# STM32H7R register map
File version: 1.3
CPU: CM7 r0p1, little endian, MPU, FPU, 4 interrupt priority bits
Registers are 32-bit, read-write, reset 0x0 unless marked. A register's access mark holds for its fields unless they carry their own. Offsets are from the block's base; [hi:lo] are bit positions; <NAME> marks a mode.

## SPDIFRX — SPDIF receiver interface
Base 0x40004000
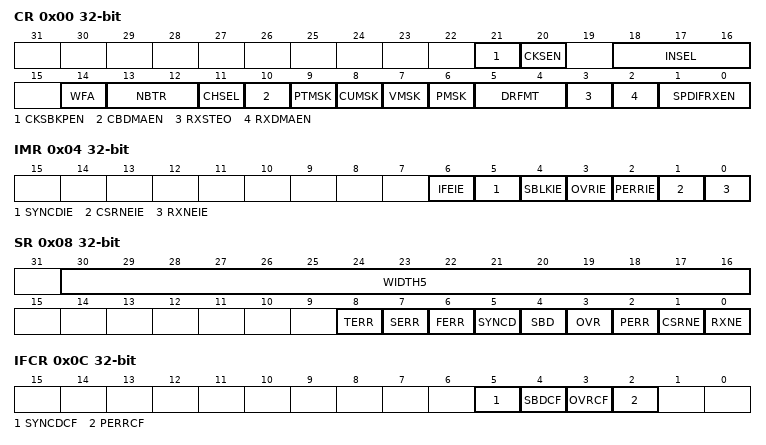
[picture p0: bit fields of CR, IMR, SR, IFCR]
0x00 CR — SPDIFRX control register
  [21] CKSBKPEN — Backup symbol clock enable This bit is set/reset by software.
  [20] CKSEN — Symbol clock enable This bit is set/reset by software.
  [18:16] INSEL — SPDIFRX input selection other: reserved
  [14] WFA — Wait for activity<sup>(1)</sup> This bit is set/reset by software.
  [13:12] NBTR — Maximum allowed re-tries during synchronization phase<sup>(1)</sup>
  [11] CHSEL — Channel selection<sup>(1)</sup> This bit is set/reset by software.
  [10] CBDMAEN — Control buffer DMA enable for control flow<sup>(1)</sup> This bit is set/reset by software. Note: When this bit is set, the DMA request is made whenever the CSRNE flag is set.
  [9] PTMSK — Mask of preamble type bits<sup>(1)</sup> This bit is set/reset by software.
  [8] CUMSK — Mask of channel status and user bits<sup>(1)</sup> This bit is set/reset by software.
  [7] VMSK — Mask of validity bit<sup>(1)</sup> This bit is set/reset by software.
  [6] PMSK — Mask parity error bit<sup>(1)</sup> This bit is set/reset by software.
  [5:4] DRFMT — RX data format<sup>(1)</sup> This bit is set/reset by software.
  [3] RXSTEO — Stereo mode<sup>(1)</sup> This bit is set/reset by software. Note: This bit is used in case of overrun situation in order to handle misalignment.
  [2] RXDMAEN — Receiver DMA enable for data flow<sup>(1)</sup> This bit is set/reset by software. Note: When this bit is set, the DMA request is made whenever the RXNE flag is set.
  [1:0] SPDIFRXEN — Peripheral block enable<sup>(1)</sup> This field is modified by software. It must be used to change the peripheral phase among the three possible states: STATE_IDLE, STATE_SYNC and STATE_RCV. It is not possible to transition from STATE_RCV to STATE_SYNC, the user must first go the STATE_IDLE. Note: it is possible to transition from STATE_IDLE to STATE_RCV: in that case the peripheral transitions from STATE_IDLE to STATE_SYNC and as soon as the synchronization is performed goes to STATE_RCV.
0x04 IMR — SPDIFRX interrupt mask register
  [6] IFEIE — Serial interface error interrupt enable This bit is set and cleared by software.
  [5] SYNCDIE — Synchronization done This bit is set and cleared by software.
  [4] SBLKIE — Synchronization block detected interrupt enable This bit is set and cleared by software.
  [3] OVRIE — Overrun error interrupt enable This bit is set and cleared by software.
  [2] PERRIE — Parity error interrupt enable This bit is set and cleared by software.
  [1] CSRNEIE — Control buffer ready interrupt enable This bit is set and cleared by software.
  [0] RXNEIE — RXNE interrupt enable This bit is set and cleared by software.
0x08 SR ro — SPDIFRX status register
  [30:16] WIDTH5 — duration of 5 symbols counted with spdifrx_ker_ck This value represents the amount of spdifrx_ker_ck clock periods contained on a length of 5 consecutive symbols. This value can be used to estimate the S/PDIF symbol rate. Its accuracy is limited by the frequency of spdifrx_ker_ck. For example if the spdifrx_ker_ck is fixed to 84 MHz, and WIDTH5 = 147d. The estimated sampling rate of the S/PDIF stream is: Fs = 5 x F<sub>spdifrx_ker_ck</sub> / (WIDTH5 x 64) ~ 44.6 kHz, so the closest standard sampling rate is 44.1 kHz. Note that WIDTH5 is updated by the hardware when SYNCD goes high, and then every frame.
  [8] TERR — Time-out error This bit is set by hardware when the counter TRCNT reaches its max value. It indicates that the time interval between two transitions is too long. It generally indicates that there is no valid signal on SPDIFRX_IN input. This flag is cleared by writing SPDIFRXEN to 0. An interrupt is generated if IFEIE=1 in the SPDIFRX_IMR register.
  [7] SERR — Synchronization error This bit is set by hardware when the synchronization fails due to amount of re-tries for NBTR. This flag is cleared by writing SPDIFRXEN to 0. An interrupt is generated if IFEIE = 1 in the SPDIFRX_IMR register.
  [6] FERR — Framing error This bit is set by hardware when an error occurs during data reception: such as preamble not at the expected place, short transition not grouped by pairs. This is set by the hardware only if the synchronization is completed (SYNCD = 1). This flag is cleared by writing SPDIFRXEN to 0. An interrupt is generated if IFEIE=1 in the SPDIFRX_IMR register.
  [5] SYNCD — Synchronization done This bit is set by hardware when the initial synchronization phase is properly completed. This flag is cleared by writing a 1 to its corresponding bit on SPDIFRX_IFCR register. An interrupt is generated if SYNCDIE = 1 in the SPDIFRX_IMR register.
  [4] SBD — Synchronization block detected This bit is set by hardware when a B preamble is detected. This flag is cleared by writing a 1 to its corresponding bit on SPDIFRX_IFCR register. An interrupt is generated if SBLKIE = 1 in the SPDIFRX_IMR register.
  [3] OVR — Overrun error This bit is set by hardware when a received data is ready to be transferred in the SPDIFRX_FMTx_DR register while RXNE = 1 and both SPDIFRX_FMTx_DR and RX_BUF are full. This flag is cleared by writing a 1 to its corresponding bit on SPDIFRX_IFCR register. An interrupt is generated if OVRIE=1 in the SPDIFRX_IMR register. Note: When this bit is set, the SPDIFRX_FMTx_DR register content is not lost but the last data received are.
  [2] PERR — Parity error This bit is set by hardware when the data and status bits of the sub-frame received contain an odd number of 0 and 1. This flag is cleared by writing a 1 to its corresponding bit on SPDIFRX_IFCR register. An interrupt is generated if PIE = 1 in the SPDIFRX_IMR register.
  [1] CSRNE — Control buffer register not empty This bit is set by hardware when a valid control information is ready. This flag is cleared when reading SPDIFRX_CSR register. An interrupt is generated if CBRDYIE = 1 in the SPDIFRX_IMR register.
  [0] RXNE — Read data register not empty This bit is set by hardware when a valid data is available into SPDIFRX_FMTx_DR register. This flag is cleared by reading the SPDIFRX_FMTx_DR register. An interrupt is generated if RXNEIE=1 in the SPDIFRX_IMR register.
0x0C IFCR wo — SPDIFRX interrupt flag clear register
  [5] SYNCDCF — clears the synchronization done flag Writing 1 in this bit clears the flag SYNCD in the SPDIFRX_SR register. Reading this bit always returns the value 0.
  [4] SBDCF — clears the synchronization block detected flag Writing 1 in this bit clears the flag SBD in the SPDIFRX_SR register. Reading this bit always returns the value 0.
  [3] OVRCF — clears the overrun error flag Writing 1 in this bit clears the flag OVR in the SPDIFRX_SR register. Reading this bit always returns the value 0.
  [2] PERRCF — clears the parity error flag Writing 1 in this bit clears the flag PERR in the SPDIFRX_SR register. Reading this bit always returns the value 0.
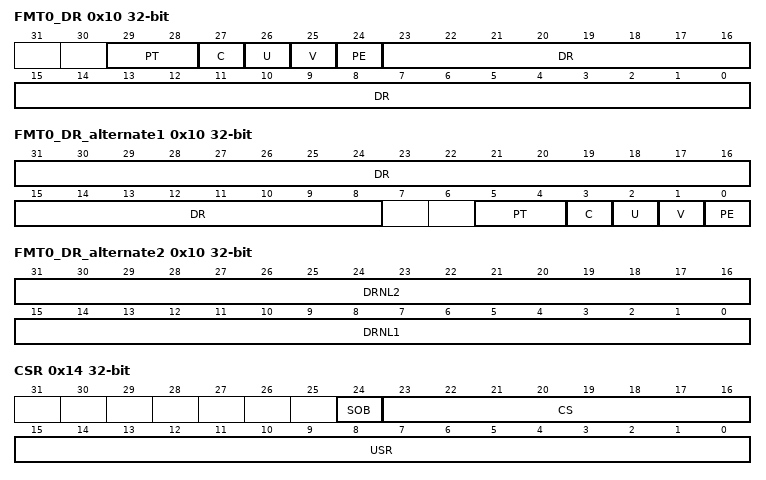
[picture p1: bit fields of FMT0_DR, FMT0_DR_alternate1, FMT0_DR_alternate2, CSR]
0x10 FMT0_DR ro — SPDIFRX data input register
  [29:28] PT — preamble type These bits indicate the preamble received. Note that if PTMSK = 1, this field is forced to zero
  [27] C — channel status bit Contains the received channel status bit, if CUMSK = 0, otherwise it is forced to 0
  [26] U — user bit Contains the received user bit, if CUMSK = 0, otherwise it is forced to 0
  [25] V — validity bit Contains the received validity bit if VMSK = 0, otherwise it is forced to 0
  [24] PE — parity error bit Contains a copy of PERR bit if PMSK = 0, otherwise it is forced to 0
  [23:0] DR — data value Contains the 24 received data bits, aligned on D[23]
0x10 FMT0_DR_alternate1 ro (alternate view of FMT0_DR) — SPDIFRX data input register
  [31:8] DR — data value Contains the 24 received data bits, aligned on D[23]
  [5:4] PT — preamble type These bits indicate the preamble received. Note that if PTMSK = 1, this field is forced to zero
  [3] C — channel Status bit Contains the received channel status bit, if CUMSK = 0, otherwise it is forced to 0
  [2] U — user bit Contains the received user bit, if CUMSK = 0, otherwise it is forced to 0
  [1] V — validity bit Contains the received validity bit if VMSK = 0, otherwise it is forced to 0
  [0] PE — parity error bit Contains a copy of PERR bit if PMSK = 0, otherwise it is forced to 0
0x10 FMT0_DR_alternate2 ro (alternate view of FMT0_DR) — SPDIFRX data input register
  [31:16] DRNL2 — data value This field contains the channel A
  [15:0] DRNL1 — data value This field contains the channel B
0x14 CSR ro — SPDIFRX channel status register
  [24] SOB — start of block This bit indicates if the bit CS[0] corresponds to the first bit of a new block
  [23:16] CS — channel A status information Bit CS[0] is the oldest value
  [15:0] USR — user data information Bit USR[0] is the oldest value, and comes from channel A, USR[1] comes channel B. So USR[n] bits come from channel A is n is even, otherwise they come from channel B.
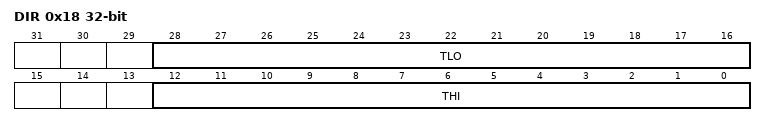
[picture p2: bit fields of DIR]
0x18 DIR ro — SPDIFRX debug information register
  [28:16] TLO — threshold LOW (TLO = 1.5 x UI / T<sub>spdifrx_ker_ck</sub>) This field contains the current threshold LOW estimation. This value can be used to estimate the sampling rate of the received stream. The accuracy of TLO is limited to a period of the spdifrx_ker_ck. The sampling rate can be estimated as follow: Sampling Rate = [2 x TLO x T<sub>spdifrx_ker_ck </sub>+/- T<sub>spdifrx_ker_ck</sub>] x 2/3 Note that TLO is updated by the hardware when SYNCD goes high, and then every frame.
  [12:0] THI — threshold HIGH (THI = 2.5 x UI / T<sub>spdifrx_ker_ck</sub>) This field contains the current threshold HIGH estimation. This value can be used to estimate the sampling rate of the received stream. The accuracy of THI is limited to a period of the spdifrx_ker_ck. The sampling rate can be estimated as follow: Sampling Rate = [2 x THI x T<sub>spdifrx_ker_ck </sub>+/- T<sub>spdifrx_ker_ck</sub>] x 2/5 Note that THI is updated by the hardware when SYNCD goes high, and then every frame.
